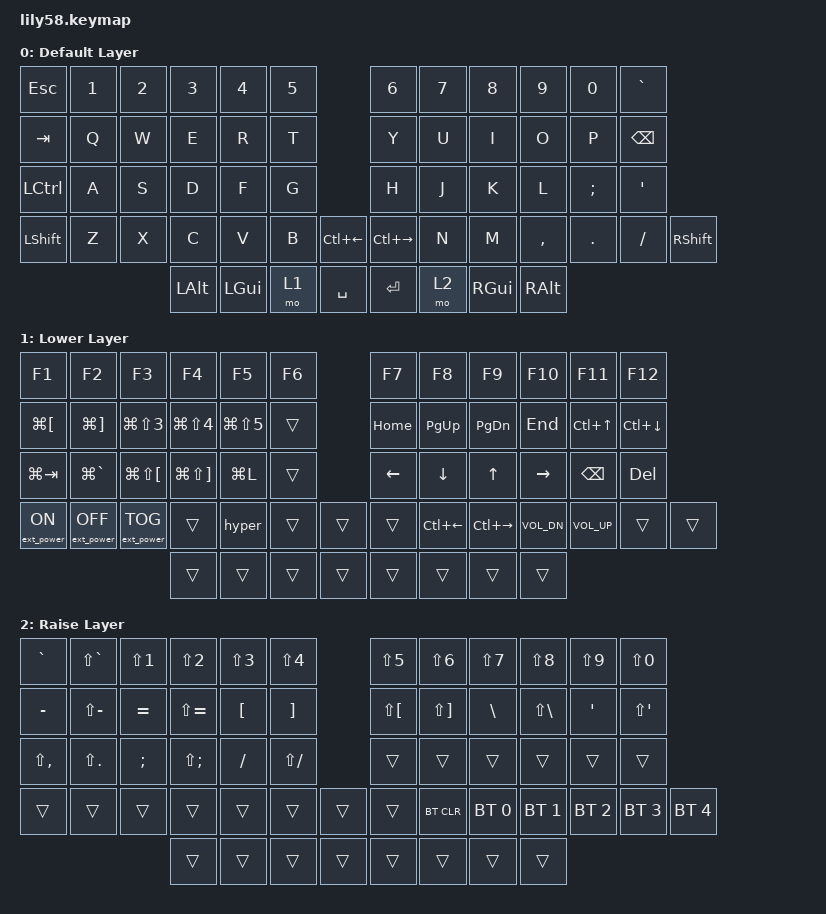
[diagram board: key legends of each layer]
/*
 * Copyright (c) 2020 The ZMK Contributors
 *
 * SPDX-License-Identifier: MIT
 */

#include <behaviors.dtsi>
#include <dt-bindings/zmk/keys.h>
#include <dt-bindings/zmk/bt.h>
#include <dt-bindings/zmk/ext_power.h>

/ {
    macros {
        hyper: hyper_sticky {
            compatible = "zmk,behavior-macro";
            #binding-cells = <0>;
            wait-ms = <0>;
            tap-ms = <0>;
            bindings = <&sk LS(LC(LA(LGUI)))>;
        };
    };

    keymap {
        compatible = "zmk,keymap";

        default_layer {
            display-name = "Default Layer";
// -----------------------------------------------------------------------------------------------------------------------
// |  ESC  |  1  |  2  |  3   |  4   |  5   |                      |  6   |  7   |  8   |  9   |  0   |   `   |
// |  TAB  |  Q  |  W  |  E   |  R   |  T   |                      |  Y   |  U   |  I   |  O   |  P   | BSPC  |
// | CTRL  |  A  |  S  |  D   |  F   |  G   |                      |  H   |  J   |  K   |  L   |  ;   |   '   |
// | SHIFT |  Z  |  X  |  C   |  V   |  B   | C+LEFT| C+RIGHT|     |  N   |  M   |  ,   |  .   |  /   | SHIFT |
//                    | ALT | CMD | LOWER | SPACE |  | ENTER | RAISE | CMD | ALT |
            bindings = <
&kp ESC   &kp N1 &kp N2 &kp N3   &kp N4   &kp N5                     &kp N6 &kp N7   &kp N8    &kp N9  &kp N0   &kp GRAVE
&kp TAB   &kp Q  &kp W  &kp E    &kp R    &kp T                      &kp Y  &kp U    &kp I     &kp O   &kp P    &kp BSPC
&kp LCTRL &kp A  &kp S  &kp D    &kp F    &kp G                      &kp H  &kp J    &kp K     &kp L   &kp SEMI &kp SQT
&kp LSHFT &kp Z  &kp X  &kp C    &kp V    &kp B  &kp LC(LEFT) &kp LC(RIGHT) &kp N  &kp M    &kp COMMA &kp DOT &kp FSLH &kp RSHFT
                        &kp LALT &kp LGUI &mo 1     &kp SPACE &kp RET &mo 2       &kp RGUI &kp RALT
            >;

            sensor-bindings = <&inc_dec_kp C_VOL_UP C_VOL_DN>;
        };

        lower_layer {
            display-name = "Lower Layer";
// Nav + macOS
// |  F1  |  F2 |  F3 |  F4  |  F5  |  F6  |                      |  F7  |  F8  |  F9  |  F10 |  F11 |  F12 |
// | BACK | FWD |SCR3 | SCR4 | SCR5 |      |                      | HOME | PGUP | PGDN | END  | C+UP | C+DN |
// | CMD+TAB | CMD+` | CMD+S-[ | CMD+S-] | CMD+L |      |        | LEFT | DOWN |  UP  | RIGHT| BSPC | DEL |
// | EXT ON | EXT OFF| EXT TOG| (trans) | (trans) | (trans) | (trans) | (trans) | C+LEFT | C+RIGHT | VOL- | VOL+ | (trans) | (trans) |
            bindings = <
&kp F1     &kp F2           &kp F3            &kp F4            &kp F5       &kp F6                       &kp F7    &kp F8    &kp F9    &kp F10   &kp F11   &kp F12
&kp LG(LBKT) &kp LG(RBKT)  &kp LG(LS(N3))    &kp LG(LS(N4))    &kp LG(LS(N5)) &trans                     &kp HOME  &kp PG_UP &kp PG_DN &kp END   &kp LC(UP) &kp LC(DOWN)
&kp LG(TAB) &kp LG(GRAVE)   &kp LG(LS(LBKT))  &kp LG(LS(RBKT))  &kp LG(L)    &trans                       &kp LEFT  &kp DOWN  &kp UP    &kp RIGHT &kp BSPC  &kp DEL
&ext_power EP_ON &ext_power EP_OFF &ext_power EP_TOG &trans     &hyper       &trans    &trans   &trans    &kp LC(LEFT) &kp LC(RIGHT) &kp C_VOL_DN &kp C_VOL_UP &trans  &trans
                                              &trans            &trans       &trans    &trans   &trans    &trans       &trans   &trans
            >;

            sensor-bindings = <&inc_dec_kp C_VOL_UP C_VOL_DN>;
        };

        raise_layer {
            display-name = "Raise Layer";
// Símbolos
// |  `  |  ~  |  !  |  @   |  #   |  $   |                      |  %   |  ^   |  &   |  *   |  (   |   )   |
// |  -  |  _  |  =  |  +   |  [   |  ]   |                      |  {   |  }   |  \   |  |   |  '   |   "   |
// |  <  |  >  |  ;  |  :   |  /   |  ?   |                      |      |      |      |      |      |       |
// |     |     |     |      |      |      |      |      |      |BT_CLR| BT0  | BT1  | BT2  | BT3  | BT4   |
            bindings = <
&kp GRAVE &kp LS(GRAVE) &kp LS(N1)  &kp LS(N2)   &kp LS(N3)   &kp LS(N4)                 &kp LS(N5)   &kp LS(N6)   &kp LS(N7)   &kp LS(N8)   &kp LS(N9)  &kp LS(N0)
&kp MINUS &kp LS(MINUS) &kp EQUAL   &kp LS(EQUAL)&kp LBKT     &kp RBKT                    &kp LS(LBKT) &kp LS(RBKT) &kp BSLH     &kp LS(BSLH) &kp SQT      &kp LS(SQT)
&kp LS(COMMA) &kp LS(DOT) &kp SEMI  &kp LS(SEMI) &kp FSLH     &kp LS(FSLH)                &trans       &trans       &trans       &trans       &trans       &trans
&trans    &trans &trans &trans  &trans  &trans   &trans   &trans    &bt BT_CLR  &bt BT_SEL 0 &bt BT_SEL 1 &bt BT_SEL 2 &bt BT_SEL 3 &bt BT_SEL 4
                        &trans  &trans  &trans    &trans   &trans    &trans      &trans    &trans
            >;

            sensor-bindings = <&inc_dec_kp C_VOL_UP C_VOL_DN>;
        };

    };
};
